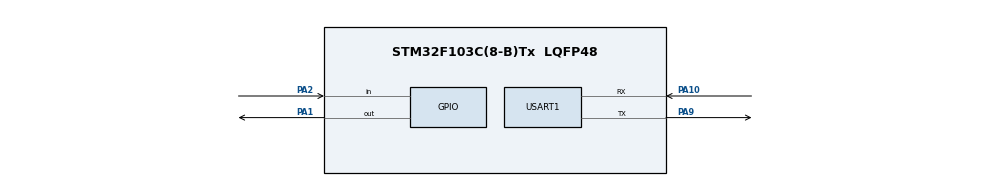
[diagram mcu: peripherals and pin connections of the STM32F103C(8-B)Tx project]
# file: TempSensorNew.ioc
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Mcu.Family=STM32F1
Mcu.Name=STM32F103C(8-B)Tx
Mcu.Package=LQFP48
NVIC.PriorityGroup=NVIC_PRIORITYGROUP_4
PA1.Signal=GPIO_Output
PA10.Mode=Asynchronous
PA10.Signal=USART1_RX
PA13.Mode=Serial_Wire
PA13.Signal=SYS_JTMS-SWDIO
PA14.Mode=Serial_Wire
PA14.Signal=SYS_JTCK-SWCLK
PA2.Signal=GPIO_Input
PA9.Mode=Asynchronous
PA9.Signal=USART1_TX
PD0-OSC_IN.Mode=HSE-External-Oscillator
PD0-OSC_IN.Signal=RCC_OSC_IN
PD1-OSC_OUT.Mode=HSE-External-Oscillator
PD1-OSC_OUT.Signal=RCC_OSC_OUT
ProjectManager.HeapSize=0x200
ProjectManager.StackSize=0x400
ProjectManager.TargetToolchain=STM32CubeIDE
RCC.APB1Freq_Value=8000000
RCC.APB2Freq_Value=8000000
USART1.VirtualMode=VM_ASYNC
board=custom

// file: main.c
 /* USER CODE BEGIN Header */
/**
  ******************************************************************************
  * @file           : main.c
  * @brief          : Main program body
  ******************************************************************************
  * @attention
  *
  * <h2><center>&copy; Copyright (c) 2019 STMicroelectronics.
  * All rights reserved.</center></h2>
  *
  * This software component is licensed by ST under BSD 3-Clause license,
  * the "License"; You may not use this file except in compliance with the
  * License. You may obtain a copy of the License at:
  *                        opensource.org/licenses/BSD-3-Clause
  *
  ******************************************************************************
  */
/* USER CODE END Header */

#include "main.h"
#include "dwt_stm32_delay.h"
#include "string.h"
#include <stdio.h>

uint8_t Rh_byte1, Rh_byte2;
uint8_t Temp_byte1, Temp_byte2;
float RH,TEMP;
uint16_t RH1,TEMP1;
uint8_t check=0;

  UART_HandleTypeDef huart1;
  GPIO_InitTypeDef GPIO_InitStruct = {0};

  void set_gpio_output(void){
	  GPIO_InitStruct.Pin = GPIO_PIN_1;
	  GPIO_InitStruct.Mode = GPIO_MODE_OUTPUT_PP;
	  GPIO_InitStruct.Pull = GPIO_NOPULL;
	  GPIO_InitStruct.Speed = GPIO_SPEED_FREQ_LOW;
	  HAL_GPIO_Init(GPIOA, &GPIO_InitStruct);
  }

  /*Configure GPIO pin : PA2 */
  void set_gpio_input(void){
	   GPIO_InitStruct.Pin = GPIO_PIN_1;
  	  GPIO_InitStruct.Mode = GPIO_MODE_INPUT;
  	  GPIO_InitStruct.Pull = GPIO_NOPULL;
  	  HAL_GPIO_Init(GPIOA, &GPIO_InitStruct);
  }

  void dht22_start(void){
	  set_gpio_output();
	  HAL_GPIO_WritePin(GPIOA, GPIO_PIN_1, 0);
	  DWT_Delay_us(500);
	  HAL_GPIO_WritePin(GPIOA, GPIO_PIN_1, 1);
	  DWT_Delay_us(30);

	  set_gpio_input();

  }

  void check_respose (void){
	  DWT_Delay_us(40);
	  if(!(HAL_GPIO_ReadPin(GPIOA, GPIO_PIN_1))){
		  DWT_Delay_us(40);
		  if((HAL_GPIO_ReadPin(GPIOA, GPIO_PIN_1))) check=1;
	  }
	  while((HAL_GPIO_ReadPin(GPIOA, GPIO_PIN_1)));
  }

  uint8_t read_data(void){
	  uint8_t i,j;
	  for (j=0;j<8;j++){
		  while(!(HAL_GPIO_ReadPin(GPIOA, GPIO_PIN_1)));
		  DWT_Delay_us(40);
		  if ((HAL_GPIO_ReadPin(GPIOA, GPIO_PIN_1))==0){
			  i&= ~(1<<(7-j));
		  }
		  else i|= (1<<(7-j));
		  while ((HAL_GPIO_ReadPin(GPIOA, GPIO_PIN_1)));
	  }
	  return i;
  }

void SystemClock_Config(void);
static void MX_GPIO_Init(void);
static void MX_USART1_UART_Init(void);

int main(void)
{

  /* MCU Configuration--------------------------------------------------------*/

  /* Reset of all peripherals, Initializes the Flash interface and the Systick. */
  HAL_Init();

  /* Configure the system clock */
  SystemClock_Config();

  /* Initialize all configured peripherals */
  MX_GPIO_Init();
  MX_USART1_UART_Init();
  /* USER CODE BEGIN 2 */
  DWT_Delay_Init ();
  /* USER CODE END 2 */
   uint8_t buffer[16];
  /* Infinite loop */
  /* USER CODE BEGIN WHILE */
  while (1)
  {
	  //HAL_UART_Transmit(&huart1, (uint8_t*)"HI\n", strlen("HI\n"), 200);
    /* USER CODE END WHILE */
	  dht22_start();
	 // HAL_UART_Transmit(&huart1, (uint8_t*)"HI01\n", strlen("HI01\n"), 200);
	  check_respose();

	  //HAL_UART_Transmit(&huart1, (uint8_t*)"HI02\n", strlen("HI02\n"), 200);
	  Rh_byte1 = read_data();
	  //HAL_UART_Transmit(&huart1, (uint8_t*)"HI03\n", strlen("HI03\n"), 200);
	  Rh_byte2 = read_data();
	 // HAL_UART_Transmit(&huart1, (uint8_t*)"HI04\n", strlen("HI04\n"), 200);
	  Temp_byte1 = read_data();
	 // HAL_UART_Transmit(&huart1, (uint8_t*)"HI05\n", strlen("HI05\n"), 200);
	  Temp_byte2 = read_data();
	 // HAL_UART_Transmit(&huart1, (uint8_t*)"HI06\n", strlen("HI06\n"), 200);
	  //sum = read_data();
	//  HAL_UART_Transmit(&huart1, (uint8_t*)"HI07\n", strlen("HI07\n"), 200);
	  TEMP1 = (Temp_byte1<<8)|Temp_byte2;
	 // HAL_UART_Transmit(&huart1, (uint8_t*)"HI08\n", strlen("HI08\n"), 200);
	  RH1 = (Rh_byte1<<8)|Rh_byte2;

	  TEMP1 = (TEMP1/10.0);
	  RH1 = (RH1/10.0);
	//  HAL_UART_Transmit(&huart1, (uint8_t*)"HI09\n", strlen("HI09\n"), 200);
	  HAL_UART_Transmit(&huart1, (uint8_t*)buffer, sprintf(buffer, "Temperature is %d \n", TEMP1), 500); // @suppress("Float formatting support")
	  HAL_UART_Transmit(&huart1, (uint8_t*)buffer, sprintf(buffer, "Humidity is %d \n", RH1), 500); // @suppress("Float formatting support")

    /* USER CODE BEGIN 3 */

	  HAL_Delay(1000);
  }
  /* USER CODE END 3 */
}

void SystemClock_Config(void)
{
  RCC_OscInitTypeDef RCC_OscInitStruct = {0};
  RCC_ClkInitTypeDef RCC_ClkInitStruct = {0};

  /** Initializes the CPU, AHB and APB busses clocks
  */
  RCC_OscInitStruct.OscillatorType = RCC_OSCILLATORTYPE_HSI;
  RCC_OscInitStruct.HSIState = RCC_HSI_ON;
  RCC_OscInitStruct.HSICalibrationValue = RCC_HSICALIBRATION_DEFAULT;
  RCC_OscInitStruct.PLL.PLLState = RCC_PLL_NONE;
  if (HAL_RCC_OscConfig(&RCC_OscInitStruct) != HAL_OK)
  {
    Error_Handler();
  }
  /** Initializes the CPU, AHB and APB busses clocks
  */
  RCC_ClkInitStruct.ClockType = RCC_CLOCKTYPE_HCLK|RCC_CLOCKTYPE_SYSCLK
                              |RCC_CLOCKTYPE_PCLK1|RCC_CLOCKTYPE_PCLK2;
  RCC_ClkInitStruct.SYSCLKSource = RCC_SYSCLKSOURCE_HSI;
  RCC_ClkInitStruct.AHBCLKDivider = RCC_SYSCLK_DIV1;
  RCC_ClkInitStruct.APB1CLKDivider = RCC_HCLK_DIV1;
  RCC_ClkInitStruct.APB2CLKDivider = RCC_HCLK_DIV1;

  if (HAL_RCC_ClockConfig(&RCC_ClkInitStruct, FLASH_LATENCY_0) != HAL_OK)
  {
    Error_Handler();
  }
}

static void MX_USART1_UART_Init(void)
{

  huart1.Instance = USART1;
  huart1.Init.BaudRate = 115200;
  huart1.Init.WordLength = UART_WORDLENGTH_8B;
  huart1.Init.StopBits = UART_STOPBITS_1;
  huart1.Init.Parity = UART_PARITY_NONE;
  huart1.Init.Mode = UART_MODE_TX_RX;
  huart1.Init.HwFlowCtl = UART_HWCONTROL_NONE;
  huart1.Init.OverSampling = UART_OVERSAMPLING_16;
  if (HAL_UART_Init(&huart1) != HAL_OK)
  {
    Error_Handler();
  }

}

static void MX_GPIO_Init(void)
{

  /* GPIO Ports Clock Enable */
  __HAL_RCC_GPIOD_CLK_ENABLE();
  __HAL_RCC_GPIOA_CLK_ENABLE();

  /*Configure GPIO pin Output Level */
  //HAL_GPIO_WritePin(GPIOA, GPIO_PIN_1, GPIO_PIN_RESET);

  /*Configure GPIO pin : PA1 */

}

void Error_Handler(void)
{
}

/************************ (C) COPYRIGHT STMicroelectronics *****END OF FILE****/
